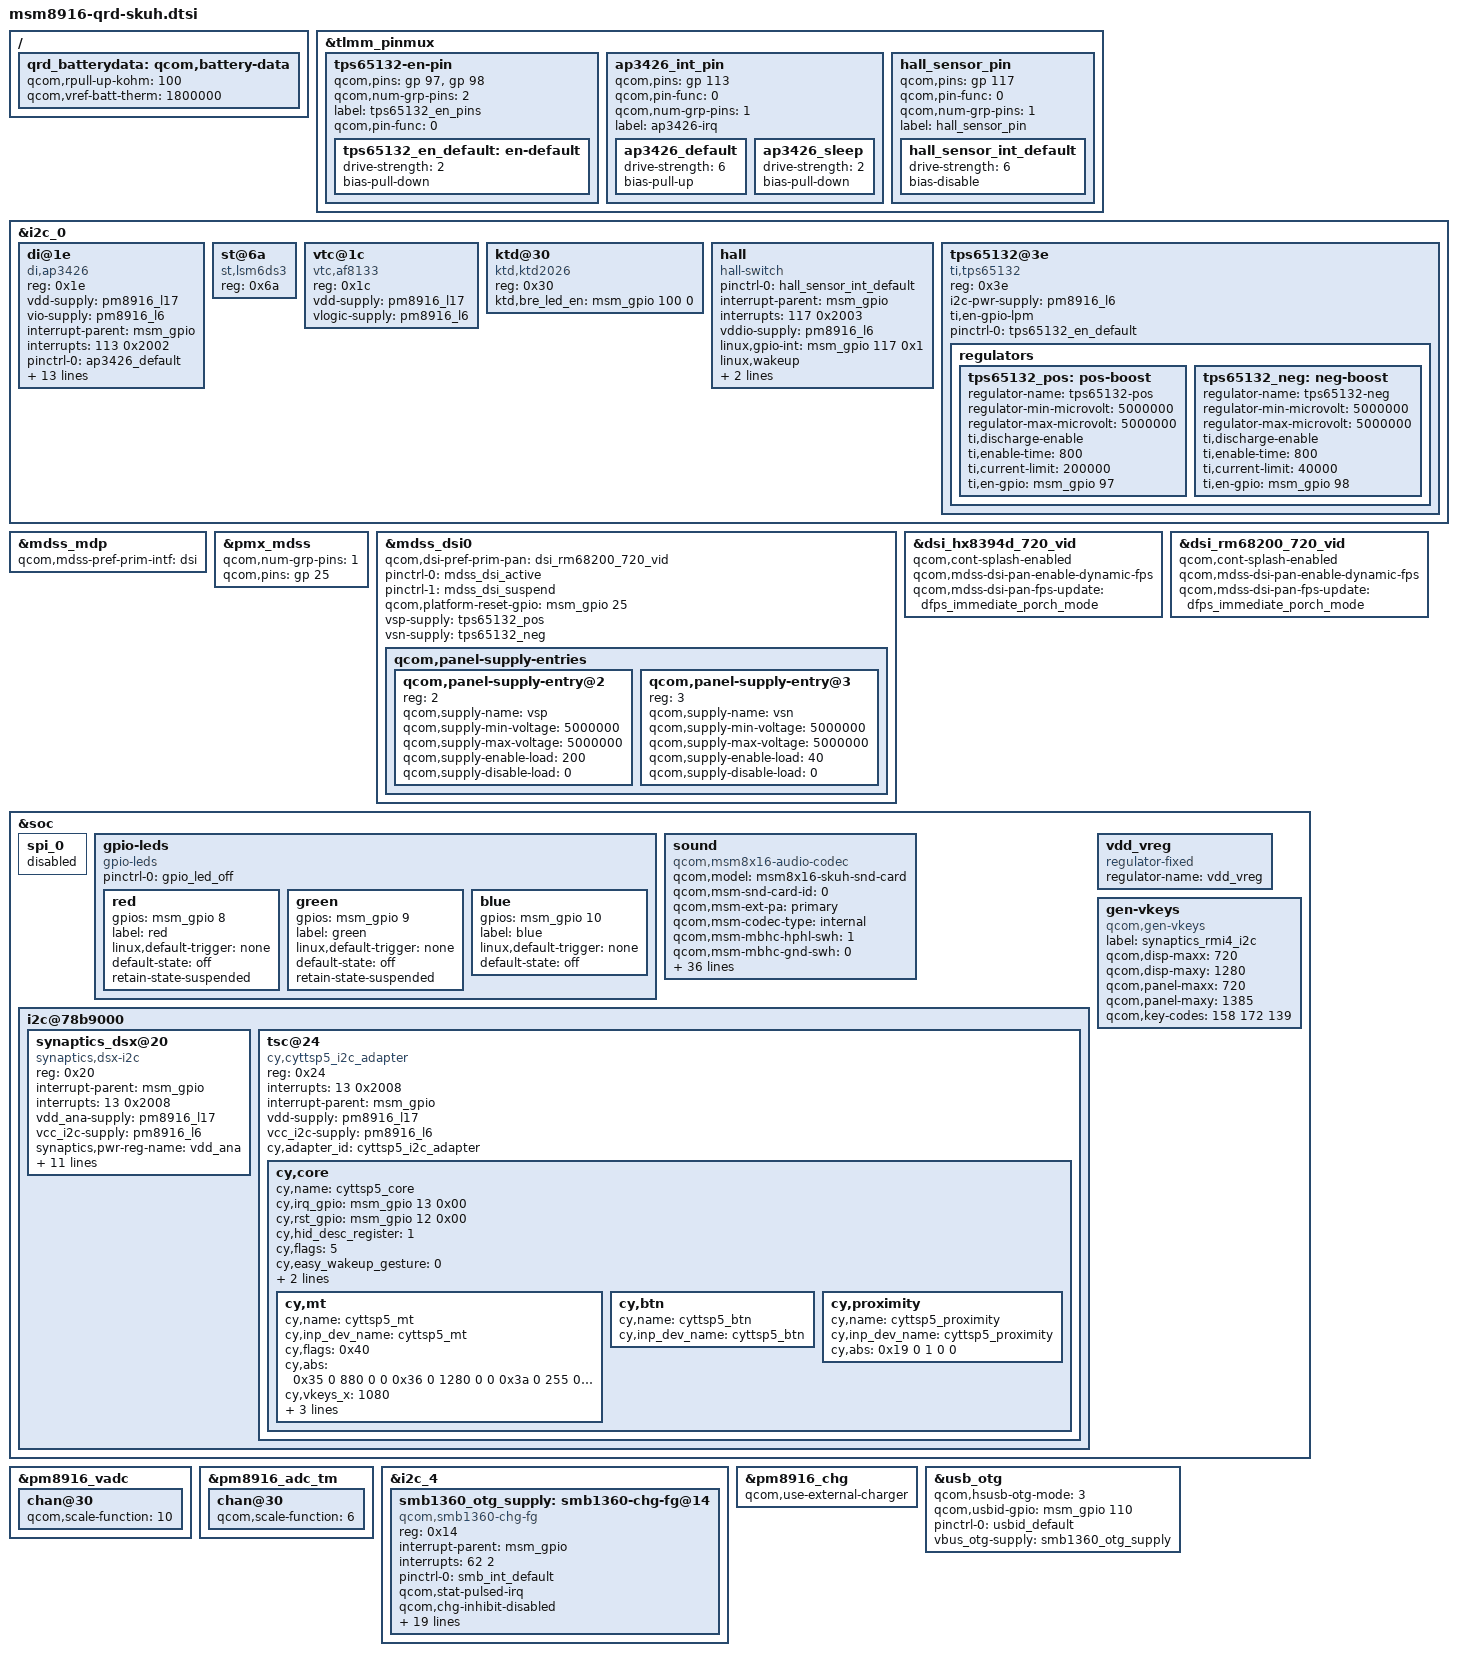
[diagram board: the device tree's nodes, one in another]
/* Copyright (c) 2014, The Linux Foundation. All rights reserved.
 *
 * This program is free software; you can redistribute it and/or modify
 * it under the terms of the GNU General Public License version 2 and
 * only version 2 as published by the Free Software Foundation.
 *
 * This program is distributed in the hope that it will be useful,
 * but WITHOUT ANY WARRANTY; without even the implied warranty of
 * MERCHANTABILITY or FITNESS FOR A PARTICULAR PURPOSE.  See the
 * GNU General Public License for more details.
 */

#include "msm8916-qrd.dtsi"
#include "dsi-panel-hx8394d-720p-video.dtsi"
#include "dsi-panel-rm68200-720p-video.dtsi"
#include "msm8916-camera-sensor-qrd.dtsi"

&tlmm_pinmux {
	tps65132-en-pin {
		qcom,pins = <&gp 97>, <&gp 98>;
		qcom,num-grp-pins = <2>;
		label = "tps65132_en_pins";
		qcom,pin-func = <0>;

		tps65132_en_default: en-default {
			drive-strength = <2>;
			bias-pull-down;
		};
	};

	ap3426_int_pin {
                qcom,pins = <&gp 113>;
                qcom,pin-func = <0>;
                qcom,num-grp-pins = <1>;
                label = "ap3426-irq";
                ap3426_default: ap3426_default {
                        drive-strength = <6>;
                        bias-pull-up;
                };
                ap3426_sleep: ap3426_sleep {
                        drive-strength = <2>;
                        bias-pull-down;
                };
        };
	
	/* lijinpei add hall sensor int-pin */
	hall_sensor_pin {
		qcom,pins = <&gp 117>;
		qcom,pin-func = <0>;
		qcom,num-grp-pins = <1>;
		label = "hall_sensor_pin";

		hall_sensor_int_default: hall_sensor_int_default {
			drive-strength = <6>;
			bias-disable;
		};
	};
};

&i2c_0 { /* BLSP1 QUP2 */

	di@1e {
    		compatible = "di,ap3426";
    		reg = <0x1e>;
    		vdd-supply = <&pm8916_l17>;
    		vio-supply = <&pm8916_l6>;
    		interrupt-parent = <&msm_gpio>;
    		interrupts = <113 0x2002>;
    		pinctrl-names = "default","sleep";
    		pinctrl-0 = <&ap3426_default>;
    		pinctrl-1 = <&ap3426_sleep>;
    		di,irq-gpio = <&msm_gpio 113 0x2002>;
    		di,als-cal = <94>;
    		di,als-gain = <0>;
   		di,als-persist = <1>;
    		di,ps-gain = <1>;
    		di,ps-persist = <2>;
    		di,ps-led-driver = <3>;
    		di,ps-mean-time = <0>;
    		di,ps-integrated-time = <0>;
    		di,ps-distance-table = <887 282 111 78 53 46>;
    		di,als-sensitivity = <50>;
    		di,wakeup-threshold = <4>;
  	};
 
	st@6a {
                compatible = "st,lsm6ds3";
                reg = <0x6a>;
        };

    vtc@1c {/*Magnetic sensor*/
                compatible = "vtc,af8133";
                reg = <0x1c>;
                vdd-supply = <&pm8916_l17>;
                vlogic-supply = <&pm8916_l6>;
	};

	ktd@30 { /* breath led */
		compatible = "ktd,ktd2026";
		reg = <0x30>;
        	/*ktd,home_key_en = <&msm_gpio 3 0>;*/
        	ktd,bre_led_en = <&msm_gpio 100 0>;
	};

	/*lijinpei add for hall sensor*/
    	hall {
        	compatible = "hall-switch";
        	pinctrl-names = "default";
        	pinctrl-0 = <&hall_sensor_int_default>;
        	interrupt-parent = <&msm_gpio>;
        	interrupts = <117 0x2003>;
        	vddio-supply = <&pm8916_l6>;
        	linux,gpio-int = <&msm_gpio 117 0x1>;
        	linux,wakeup;
        	linux,min-uv = <1650000>;
        	linux,max-uv = <3300000>;
    	};
	
	tps65132@3e {
		compatible = "ti,tps65132";
		reg = <0x3e>;
		i2c-pwr-supply = <&pm8916_l6>;
		ti,en-gpio-lpm;
		pinctrl-names = "default";
		pinctrl-0 = <&tps65132_en_default>;

		regulators {
			tps65132_pos: pos-boost {
				regulator-name = "tps65132-pos";
				regulator-min-microvolt = <5000000>;
				regulator-max-microvolt = <5000000>;
				ti,discharge-enable;
				ti,enable-time = <800>;
				ti,current-limit = <200000>;
				ti,en-gpio = <&msm_gpio 97 0>;
			};

			tps65132_neg: neg-boost {
				regulator-name = "tps65132-neg";
				regulator-min-microvolt = <5000000>;
				regulator-max-microvolt = <5000000>;
				ti,discharge-enable;
				ti,enable-time = <800>;
				ti,current-limit = <40000>;
				ti,en-gpio = <&msm_gpio 98 0>;
			};
		};
	};

};

&mdss_mdp {
	qcom,mdss-pref-prim-intf = "dsi";
};

&pmx_mdss {
	qcom,num-grp-pins = <1>;
	qcom,pins = <&gp 25>;
};
&mdss_dsi0 {
	qcom,dsi-pref-prim-pan = <&dsi_hx8394d_720_vid>;
	pinctrl-names = "mdss_default", "mdss_sleep";
	pinctrl-0 = <&mdss_dsi_active>;
	pinctrl-1 = <&mdss_dsi_suspend>;

	qcom,platform-reset-gpio = <&msm_gpio 25 0>;

	vsp-supply = <&tps65132_pos>;
	vsn-supply = <&tps65132_neg>;
	qcom,panel-supply-entries {
		#address-cells = <1>;
		#size-cells = <0>;

		qcom,panel-supply-entry@2 {
			reg = <2>;
			qcom,supply-name = "vsp";
			qcom,supply-min-voltage = <5000000>;
			qcom,supply-max-voltage = <5000000>;
			qcom,supply-enable-load = <200>;
			qcom,supply-disable-load = <0>;
		};

		qcom,panel-supply-entry@3 {
			reg = <3>;
			qcom,supply-name = "vsn";
			qcom,supply-min-voltage = <5000000>;
			qcom,supply-max-voltage = <5000000>;
			qcom,supply-enable-load = <40>;
			qcom,supply-disable-load = <0>;
		};
	};
};
&mdss_dsi0 {
	qcom,dsi-pref-prim-pan = <&dsi_rm68200_720_vid>;
	pinctrl-names = "mdss_default", "mdss_sleep";
	pinctrl-0 = <&mdss_dsi_active>;
	pinctrl-1 = <&mdss_dsi_suspend>;

	qcom,platform-reset-gpio = <&msm_gpio 25 0>;

	vsp-supply = <&tps65132_pos>;
	vsn-supply = <&tps65132_neg>;
	qcom,panel-supply-entries {
		#address-cells = <1>;
		#size-cells = <0>;

		qcom,panel-supply-entry@2 {
			reg = <2>;
			qcom,supply-name = "vsp";
			qcom,supply-min-voltage = <5000000>;
			qcom,supply-max-voltage = <5000000>;
			qcom,supply-enable-load = <200>;
			qcom,supply-disable-load = <0>;
		};

		qcom,panel-supply-entry@3 {
			reg = <3>;
			qcom,supply-name = "vsn";
			qcom,supply-min-voltage = <5000000>;
			qcom,supply-max-voltage = <5000000>;
			qcom,supply-enable-load = <40>;
			qcom,supply-disable-load = <0>;
		};
	};
};

&dsi_hx8394d_720_vid {
	qcom,cont-splash-enabled;
	/*qcom,esd-check-enabled;*/
	qcom,mdss-dsi-pan-enable-dynamic-fps;
	qcom,mdss-dsi-pan-fps-update = "dfps_immediate_porch_mode";
};
&dsi_rm68200_720_vid {
	qcom,cont-splash-enabled;
	/*qcom,esd-check-enabled;*/
	qcom,mdss-dsi-pan-enable-dynamic-fps;
	qcom,mdss-dsi-pan-fps-update = "dfps_immediate_porch_mode";
};
&soc {
	spi_0 {
		status = "disabled";
	};

	gpio-leds {
		compatible = "gpio-leds";
		status = "okay";
		pinctrl-names = "default";
		pinctrl-0 = <&gpio_led_off>;

		red {
			gpios = <&msm_gpio 8 0>;
			label = "red";
			linux,default-trigger = "none";
			default-state = "off";
			retain-state-suspended;
		};

		green {
			gpios = <&msm_gpio 9 0>;
			label = "green";
			linux,default-trigger = "none";
			default-state = "off";
			retain-state-suspended;
		};

		blue {
			gpios = <&msm_gpio 10 0>;
			label = "blue";
			linux,default-trigger = "none";
			default-state = "off";
		};
	};

	sound {
			compatible = "qcom,msm8x16-audio-codec";
			qcom,model = "msm8x16-skuh-snd-card";
			qcom,msm-snd-card-id = <0>;
			qcom,msm-ext-pa = "primary";
			qcom,msm-codec-type = "internal";
			qcom,msm-mbhc-hphl-swh = <1>;
			qcom,msm-mbhc-gnd-swh = <0>;
			pinctrl-names = "cdc_lines_act",
					"cdc_lines_sus";
			pinctrl-0 = <&cdc_pdm_lines_act>;
			pinctrl-1 = <&cdc_pdm_lines_sus>;
			qcom,ext-spk-amp-gpio = <&msm_gpio 0 0>;
			asoc-platform = <&pcm0>, <&pcm1>, <&voip>, <&voice>,
					<&loopback>, <&compress>, <&hostless>,
					<&afe>, <&lsm>, <&routing>, <&lpa>;
			asoc-platform-names = "msm-pcm-dsp.0", "msm-pcm-dsp.1",
					"msm-voip-dsp", "msm-pcm-voice", "msm-pcm-loopback",
					"msm-compress-dsp", "msm-pcm-hostless", "msm-pcm-afe",
					"msm-lsm-client", "msm-pcm-routing", "msm-pcm-lpa";
			asoc-cpu = <&dai_pri_auxpcm>, <&dai_hdmi>,
					<&dai_mi2s0>, <&dai_mi2s1>, <&dai_mi2s2>, <&dai_mi2s3>,
					<&sb_0_rx>, <&sb_0_tx>, <&sb_1_rx>, <&sb_1_tx>,
					<&sb_3_rx>, <&sb_3_tx>, <&sb_4_rx>, <&sb_4_tx>,
					<&bt_sco_rx>, <&bt_sco_tx>, <&int_fm_rx>, <&int_fm_tx>,
					<&afe_pcm_rx>, <&afe_pcm_tx>, <&afe_proxy_rx>,
					<&afe_proxy_tx>, <&incall_record_rx>,
					<&incall_record_tx>, <&incall_music_rx>,
					<&incall_music_2_rx>;
			asoc-cpu-names = "msm-dai-q6-auxpcm.1", "msm-dai-q6-hdmi.8",
					"msm-dai-q6-mi2s.0", "msm-dai-q6-mi2s.1",
					"msm-dai-q6-mi2s.2", "msm-dai-q6-mi2s.3",
					"msm-dai-q6-dev.16384", "msm-dai-q6-dev.16385",
					"msm-dai-q6-dev.16386", "msm-dai-q6-dev.16387",
					"msm-dai-q6-dev.16390", "msm-dai-q6-dev.16391",
					"msm-dai-q6-dev.16392", "msm-dai-q6-dev.16393",
					"msm-dai-q6-dev.12288", "msm-dai-q6-dev.12289",
					"msm-dai-q6-dev.12292", "msm-dai-q6-dev.12293",
					"msm-dai-q6-dev.224", "msm-dai-q6-dev.225",
					"msm-dai-q6-dev.241", "msm-dai-q6-dev.240",
					"msm-dai-q6-dev.32771", "msm-dai-q6-dev.32772",
					"msm-dai-q6-dev.32773", "msm-dai-q6-dev.32770";
			asoc-codec = <&stub_codec>, <&pm8916_tombak_dig>;
			asoc-codec-names = "msm-stub-codec.1", "tombak_codec";
	};

	i2c@78b9000 { /* BLSP1 QUP5 */
		synaptics_dsx@20 {
                compatible = "synaptics,dsx-i2c";
                reg = <0x20>;
                interrupt-parent = <&msm_gpio>;
                interrupts = <13 0x2008>;
                vdd_ana-supply = <&pm8916_l17>;
                vcc_i2c-supply = <&pm8916_l6>;
                synaptics,pwr-reg-name = "vdd_ana";
                synaptics,bus-reg-name = "vcc_i2c";
                synaptics,irq-gpio = <&msm_gpio 13 0x00>;
                synaptics,irq-on-state = <0>;
                synaptics,irq-flags = <0x2008>; /* IRQF_ONESHOT | IRQF_TRIGGER_LOW */
                synaptics,reset-gpio = <&msm_gpio 12 0x00>;
		synaptics,reset-on-state = <0>;
		synaptics,reset-active-ms = <50>;
                synaptics,power-delay-ms = <200>;
                synaptics,reset-delay-ms = <200>;
                synaptics,max-y-for-2d = <1280>; /* remove if no virtual buttons */
                /*synaptics,vir-button-codes = <102 100 900 100 60 158 300 900 100 60>;*/
		synaptics,cap-button-codes = <139 /*KEY_MENU*/
					      172 /*KEY_HOME*/
					      158>; /*KEY_BACK*/
                };
	
		tsc@24 {
                        compatible = "cy,cyttsp5_i2c_adapter";
                        reg = <0x24>;
                        interrupts = <13 0x2008>;
                        interrupt-parent = <&msm_gpio>;
                        vdd-supply = <&pm8916_l17>;
                        vcc_i2c-supply = <&pm8916_l6>;
                        cy,adapter_id = "cyttsp5_i2c_adapter";
                        cy,core {
                                cy,name = "cyttsp5_core";

                                cy,irq_gpio = <&msm_gpio 13 0x00>;
                                cy,rst_gpio = <&msm_gpio 12 0x00>;
                                cy,hid_desc_register = <1>;

                                /* CY_CORE_FLAG_WAKE_ON_GESTURE */
                                cy,flags = <5>;

                                /* CY_CORE_EWG_TAP_TAP | CY_CORE_EWG_TWO_FINGER_SLIDE */
                                cy,easy_wakeup_gesture = <0>;
                                cy,btn_keys = <158 /* KEY_MENU */
                                               172 /* KEY_HOME */
                                               139>; /* KEY_BACK */

                                cy,btn_keys-tag = <0>;

                                cy,mt {
                                        cy,name = "cyttsp5_mt";
                                        cy,inp_dev_name = "cyttsp5_mt";
                                        /* CY_MT_FLAG_FLIP | CY_MT_FLAG_INV_X | CY_MT_FLAG_INV_Y */
                                        cy,flags = <0x40>;
                                        cy,abs =
                                                /* ABS_MT_POSITION_X, CY_ABS_MIN_X, CY_ABS_MAX_X, 0, 0 */
                                                <0x35 0 880 0 0
                                                /* ABS_MT_POSITION_Y, CY_ABS_MIN_Y, CY_ABS_MAX_Y, 0, 0 */
                                                0x36 0 1280 0 0
                                                /* ABS_MT_PRESSURE, CY_ABS_MIN_P, CY_ABS_MAX_P, 0, 0 */
                                                0x3a 0 255 0 0
                                                /* CY_IGNORE_VALUE, CY_ABS_MIN_W, CY_ABS_MAX_W, 0, 0 */
                                                0xffff 0 255 0 0
                                                /* ABS_MT_TRACKING_ID, CY_ABS_MIN_T, CY_ABS_MAX_T, 0, 0 */
                                                0x39 0 15 0 0
                                                /* ABS_MT_TOUCH_MAJOR, 0, 255, 0, 0 */
                                                0x30 0 255 0 0
                                                /* ABS_MT_TOUCH_MINOR, 0, 255, 0, 0 */
                                                0x31 0 255 0 0
                                                /* ABS_MT_ORIENTATION, -127, 127, 0, 0 */
                                                0x34 0xffffff81 127 0 0
                                                /* ABS_MT_TOOL_TYPE, 0, MT_TOOL_MAX, 0, 0 */
                                                0x37 0 1 0 0
                                               /* ABS_DISTANCE, 0, 255, 0, 0 */
                                                0x19 0 255 0 0>;

                                        cy,vkeys_x = <1080>;
                                        cy,vkeys_y = <1920>;
                                        cy,virtual_keys = /* KeyCode CenterX CenterY Width Height */
                                                /* KEY_BACK */
                                                <158 1360 90 160 180
                                                /* KEY_MENU */
                                                139 1360 270 160 180
                                                /* KEY_HOMEPAGE */
                                                172 1360 450 160 180
                                                /* KEY SEARCH */
                                                217 1360 630 160 180>;
                                };
                                cy,btn {
                                        cy,name = "cyttsp5_btn";
                                        cy,inp_dev_name = "cyttsp5_btn";
                                };
                                cy,proximity {
                                        cy,name = "cyttsp5_proximity";

                                        cy,inp_dev_name = "cyttsp5_proximity";
                                        cy,abs =
                                                /* ABS_DISTANCE, CY_PROXIMITY_MIN_VAL, CY_PROXIMITY_MAX_VAL, 0, 0 */
                                                <0x19 0 1 0 0>;
                                };
                        };
                };
	};

	vdd_vreg: vdd_vreg {
		compatible = "regulator-fixed";
		status = "ok";
		regulator-name = "vdd_vreg";
	};

	gen-vkeys {
		compatible = "qcom,gen-vkeys";
		label = "synaptics_rmi4_i2c";
		qcom,disp-maxx = <720>;
		qcom,disp-maxy = <1280>;
		qcom,panel-maxx = <720>;
		qcom,panel-maxy = <1385>;
		qcom,key-codes = <158 172 139>;
	};
};

&pm8916_vadc {
	chan@30 {
		qcom,scale-function = <10>;
	};
};

&pm8916_adc_tm {
	chan@30 {
		qcom,scale-function = <6>;
	};
};

&i2c_4 {
        smb1360_otg_supply: smb1360-chg-fg@14 {
                compatible = "qcom,smb1360-chg-fg";
                reg = <0x14>;
                interrupt-parent = <&msm_gpio>;
                interrupts = <62 2>;
                pinctrl-names = "default";
                pinctrl-0 = <&smb_int_default>;
                qcom,stat-pulsed-irq;
                qcom,chg-inhibit-disabled;
                qcom,float-voltage-mv = <4350>;
                qcom,iterm-ma = <200>;
                qcom,charging-timeout = <384>;
                qcom,otg-batt-curr-limit = <950>;
                qcom,recharge-thresh-mv = <100>;
                qcom,thermal-mitigation = <1500 700 600 0>;
                qcom,fg-auto-recharge-soc = <99>;
                qcom,empty-soc-disabled;
                regulator-name = "smb1360_otg_vreg";
                qcom,awake-min-soc;
                qcom,batt-profile-select;
                qcom,smb1360-vadc = <&pm8916_vadc>;
                qcom,batt-id-vref-uv = <1800000>;
                qcom,batt-id-rpullup-kohm = <100>;
                qcom,profile-a-rid-kohm = <33>;
                qcom,profile-b-rid-kohm = <83>;
                qcom,config-hard-thresholds;
                qcom,hot-bat-decidegc = <550>;
                qcom,cold-bat-decidegc = <(-150)>;
        };
};

&pm8916_chg {
//	qcom,vddmax-mv = <4350>;
//	qcom,vddsafe-mv = <4380>;
//	qcom,vinmin-mv = <4470>;
//	qcom,batt-hot-percentage = <35>;
//	qcom,batt-cold-percentage = <70>;
//	qcom,tchg-mins = <360>;
//	status = "okay";
	status = "ok";
        qcom,use-external-charger;
};

/ {
	qrd_batterydata: qcom,battery-data {
		qcom,rpull-up-kohm = <100>;
		qcom,vref-batt-therm = <1800000>;

		//#include "batterydata-qrd-skuh-4v35-2000mah.dtsi"
		#include "batterydata-zx55q05-4v35-3000mah.dtsi"
	};
};
/*
&pm8916_bms {
	status = "ok";
	qcom,battery-data = <&qrd_batterydata>;
};

&sdc2_cd_on {
	/delete-property/ bias-pull-up;
	bias-disable;
};

&sdhc_2 {
	qcom,vdd-always-on;
	qcom,vdd-lpm-sup;

	qcom,vdd-current-level = <4000 400000>;
};
*/
&usb_otg {
       qcom,hsusb-otg-mode = <3>;
       qcom,usbid-gpio = <&msm_gpio 110 0>;
       pinctrl-names = "default";
       pinctrl-0 = <&usbid_default>;
       vbus_otg-supply = <&smb1360_otg_supply>;
};
